// Create by TSMaster

VERSION ""

NS_ :

BS_:

BU_:

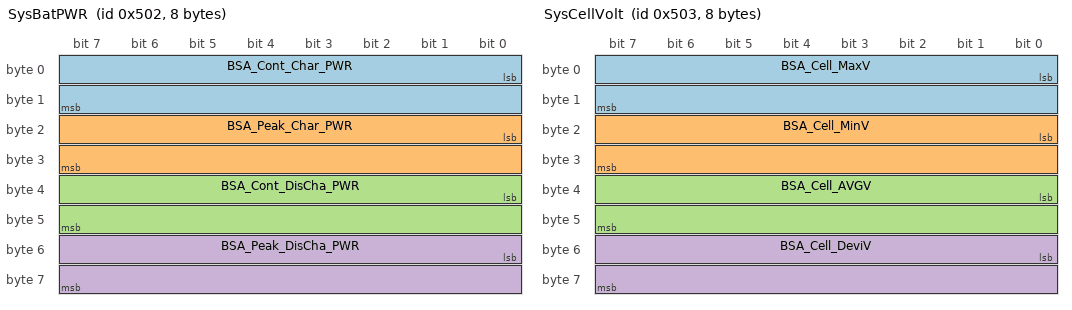
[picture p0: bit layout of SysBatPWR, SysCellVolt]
BO_ 1282 SysBatPWR: 8 Vector__XXX
 SG_ BSA_Cont_Char_PWR : 0|16@1+ (0.1,0) [0.0|200.0] "" Vector__XXX
 SG_ BSA_Peak_Char_PWR : 16|16@1+ (0.1,0) [0.0|300.0] "" Vector__XXX
 SG_ BSA_Cont_DisCha_PWR : 32|16@1+ (0.1,0) [0.0|600.0] "" Vector__XXX
 SG_ BSA_Peak_DisCha_PWR : 48|16@1+ (0.1,0) [0.0|800.0] "" Vector__XXX

BO_ 1283 SysCellVolt: 8 Vector__XXX
 SG_ BSA_Cell_MaxV : 0|16@1+ (0.001,0) [2.8|4.5] "" Vector__XXX
 SG_ BSA_Cell_MinV : 16|16@1+ (0.001,0) [2.8|4.5] "" Vector__XXX
 SG_ BSA_Cell_AVGV : 32|16@1+ (0.001,0) [2.8|4.5] "" Vector__XXX
 SG_ BSA_Cell_DeviV : 48|16@1+ (1.0,0) [0.0|1000.0] "" Vector__XXX

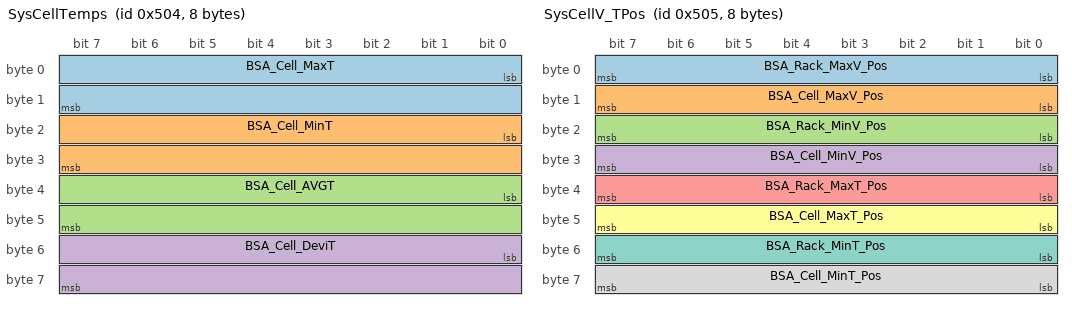
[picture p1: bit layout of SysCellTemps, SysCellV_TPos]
BO_ 1284 SysCellTemps: 8 Vector__XXX
 SG_ BSA_Cell_MaxT : 0|16@1- (0.1,0) [-40.0|100.0] "" Vector__XXX
 SG_ BSA_Cell_MinT : 16|16@1- (0.1,0) [-40.0|100.0] "" Vector__XXX
 SG_ BSA_Cell_AVGT : 32|16@1- (0.1,0) [-40.0|100.0] "" Vector__XXX
 SG_ BSA_Cell_DeviT : 48|16@1+ (0.1,0) [0.0|25.0] "" Vector__XXX

BO_ 1285 SysCellV_TPos: 8 Vector__XXX
 SG_ BSA_Rack_MaxV_Pos : 0|8@1+ (1.0,0) [1.0|10.0] "" Vector__XXX
 SG_ BSA_Cell_MaxV_Pos : 8|8@1+ (1.0,0) [1.0|288.0] "" Vector__XXX
 SG_ BSA_Rack_MinV_Pos : 16|8@1+ (1.0,0) [1.0|10.0] "" Vector__XXX
 SG_ BSA_Cell_MinV_Pos : 24|8@1+ (1.0,0) [1.0|288.0] "" Vector__XXX
 SG_ BSA_Rack_MaxT_Pos : 32|8@1+ (1.0,0) [1.0|10.0] "" Vector__XXX
 SG_ BSA_Cell_MaxT_Pos : 40|8@1+ (1.0,0) [1.0|288.0] "" Vector__XXX
 SG_ BSA_Rack_MinT_Pos : 48|8@1+ (1.0,0) [1.0|10.0] "" Vector__XXX
 SG_ BSA_Cell_MinT_Pos : 56|8@1+ (1.0,0) [1.0|288.0] "" Vector__XXX

BO_ 1286 SysBatProtect: 8 Vector__XXX
 SG_ BSA_Alarm_OC : 0|1@1+ (1.0,0) [0.0|1.0] "" Vector__XXX
 SG_ BSA_Alarm_SOC_OV : 1|1@1+ (1.0,0) [0.0|1.0] "" Vector__XXX
 SG_ BSA_Alarm_SOC_UN : 2|1@1+ (1.0,0) [0.0|1.0] "" Vector__XXX
 SG_ BSA_Alarm_OV : 3|1@1+ (1.0,0) [0.0|1.0] "" Vector__XXX
 SG_ BSA_Alarm_UV : 4|1@1+ (1.0,0) [0.0|1.0] "" Vector__XXX
 SG_ BSA_Alarm_Cell_OV : 5|1@1+ (1.0,0) [0.0|1.0] "" Vector__XXX
 SG_ BSA_Alarm__Cell_UV : 6|1@1+ (1.0,0) [0.0|1.0] "" Vector__XXX
 SG_ BSA_Alarm_Cell_UnBalaV : 7|1@1+ (1.0,0) [0.0|1.0] "" Vector__XXX
 SG_ BSA_Alarm_Dischar_Cell_OT : 8|1@1+ (1.0,0) [0.0|1.0] "" Vector__XXX
 SG_ BSA_Alarm_Char_Cell_OT : 9|1@1+ (1.0,0) [0.0|1.0] "" Vector__XXX
 SG_ BSA_Alarm_Char_Cell_UT : 10|1@1+ (1.0,0) [0.0|1.0] "" Vector__XXX
 SG_ BSA_Alarm_Dischar_Cell_UT : 11|1@1+ (1.0,0) [0.0|1.0] "" Vector__XXX
 SG_ BSA_Alarm_Cell_UnBalaT : 12|1@1+ (1.0,0) [0.0|1.0] "" Vector__XXX
 SG_ BSA_Alarm_Const_OP : 13|1@1+ (1.0,0) [0.0|1.0] "" Vector__XXX
 SG_ BSA_Alarm_Peak_OP : 14|1@1+ (1.0,0) [0.0|1.0] "" Vector__XXX
 SG_ BSA_Fault_OC : 16|1@1+ (1.0,0) [0.0|1.0] "" Vector__XXX
 SG_ BSA_Fault_SOC_OV : 17|1@1+ (1.0,0) [0.0|1.0] "" Vector__XXX
 SG_ BSA_Fault_SOC_UN : 18|1@1+ (1.0,0) [0.0|1.0] "" Vector__XXX
 SG_ BSA_Fault_OV : 19|1@1+ (1.0,0) [0.0|1.0] "" Vector__XXX
 SG_ BSA_Fault_UV : 20|1@1+ (1.0,0) [0.0|1.0] "" Vector__XXX
 SG_ BSA_Fault_Cell_OV : 21|1@1+ (1.0,0) [0.0|1.0] "" Vector__XXX
 SG_ BSA_Fault__Cell_UV : 22|1@1+ (1.0,0) [0.0|1.0] "" Vector__XXX
 SG_ BSA_Fault_Cell_UnBalaV : 23|1@1+ (1.0,0) [0.0|1.0] "" Vector__XXX
 SG_ BSA_Fault_Dischar_Cell_OT : 24|1@1+ (1.0,0) [0.0|1.0] "" Vector__XXX
 SG_ BSA_Fault_Char_Cell_OT : 25|1@1+ (1.0,0) [0.0|1.0] "" Vector__XXX
 SG_ BSA_Fault_Char_Cell_UT : 26|1@1+ (1.0,0) [0.0|1.0] "" Vector__XXX
 SG_ BSA_Fault_Dischar_Cell_UT : 27|1@1+ (1.0,0) [0.0|1.0] "" Vector__XXX
 SG_ BSA_Fault_Cell_UnBalaT : 28|1@1+ (1.0,0) [0.0|1.0] "" Vector__XXX
 SG_ BSA_Fault_Const_OP : 29|1@1+ (1.0,0) [0.0|1.0] "" Vector__XXX
 SG_ BSA_Fault_Peak_OP : 30|1@1+ (1.0,0) [0.0|1.0] "" Vector__XXX
 SG_ BSA_Prtct_OC : 32|1@1+ (1.0,0) [0.0|1.0] "" Vector__XXX
 SG_ BSA_Prtct_SOC_OV : 33|1@1+ (1.0,0) [0.0|1.0] "" Vector__XXX
 SG_ BSA_Prtct_SOC_UN : 34|1@1+ (1.0,0) [0.0|1.0] "" Vector__XXX
 SG_ BSA_Prtct_OV : 35|1@1+ (1.0,0) [0.0|1.0] "" Vector__XXX
 SG_ BSA_Prtct_UV : 36|1@1+ (1.0,0) [0.0|1.0] "" Vector__XXX
 SG_ BSA_Prtct_Cell_OV : 37|1@1+ (1.0,0) [0.0|1.0] "" Vector__XXX
 SG_ BSA_Prtct__Cell_UV : 38|1@1+ (1.0,0) [0.0|1.0] "" Vector__XXX
 SG_ BSA_Prtct_Cell_UnBalaV : 39|1@1+ (1.0,0) [0.0|1.0] "" Vector__XXX
 SG_ BSA_Prtct_Dischar_Cell_OT : 40|1@1+ (1.0,0) [0.0|1.0] "" Vector__XXX
 SG_ BSA_Prtct_Char_Cell_OT : 41|1@1+ (1.0,0) [0.0|1.0] "" Vector__XXX
 SG_ BSA_Prtct_Char_Cell_UT : 42|1@1+ (1.0,0) [0.0|1.0] "" Vector__XXX
 SG_ BSA_Prtct_Dischar_Cell_UT : 43|1@1+ (1.0,0) [0.0|1.0] "" Vector__XXX
 SG_ BSA_Prtct_Cell_UnBalaT : 44|1@1+ (1.0,0) [0.0|1.0] "" Vector__XXX
 SG_ BSA_Prtct_Continuously_OP : 45|1@1+ (1.0,0) [0.0|1.0] "" Vector__XXX
 SG_ BSA_Prtct_Peak_OP : 46|1@1+ (1.0,0) [0.0|1.0] "" Vector__XXX
 SG_ BSA_Prtct_IntCOM : 47|1@1+ (1.0,0) [0.0|1.0] "" Vector__XXX
 SG_ BSA_Prtct_ExtOM : 48|1@1+ (1.0,0) [0.0|1.0] "" Vector__XXX
 SG_ BSA_Prtct_RelayErr : 49|1@1+ (1.0,0) [0.0|1.0] "" Vector__XXX
 SG_ BSA_Prtct_WaterLeak : 50|1@1+ (1.0,0) [0.0|1.0] "" Vector__XXX
 SG_ BSA_Prtct_InsulationReg : 51|1@1+ (1.0,0) [0.0|1.0] "" Vector__XXX
 SG_ BSA_Prtct_MDSFuse : 52|1@1+ (1.0,0) [0.0|1.0] "" Vector__XXX
 SG_ BSA_Prtct_Cooling_System : 53|1@1+ (1.0,0) [0.0|1.0] "" Vector__XXX
 SG_ PMS_PAR_RelayErr : 54|1@1+ (1.0,0) [0.0|1.0] "" Vector__XXX
 SG_ PMS_PAR_SEQErr : 55|1@1+ (1.0,0) [0.0|1.0] "" Vector__XXX
 SG_ BPU_PAR_RelayErr : 56|1@1+ (1.0,0) [0.0|1.0] "" Vector__XXX
 SG_ BRA_PAR_RelayErr : 57|1@1+ (1.0,0) [0.0|1.0] "" Vector__XXX

BO_ 1287 SysBatDIO: 8 Vector__XXX
 SG_ BSA_DO_Prly : 0|1@1+ (1.0,0) [0.0|1.0] "" Vector__XXX
 SG_ BSA_DO_Nrly : 1|1@1+ (1.0,0) [0.0|1.0] "" Vector__XXX
 SG_ BSA_DO_ProRly : 2|1@1+ (1.0,0) [0.0|1.0] "" Vector__XXX
 SG_ BSA_DO_Buzzer : 3|1@1+ (1.0,0) [0.0|1.0] "" Vector__XXX
 SG_ BSA_DO_PwrLamp : 4|1@1+ (1.0,0) [0.0|1.0] "" Vector__XXX
 SG_ BSA_DO_Spare06 : 5|1@1+ (1.0,0) [0.0|1.0] "" Vector__XXX
 SG_ BSA_DO_Spare07 : 6|1@1+ (1.0,0) [0.0|1.0] "" Vector__XXX
 SG_ BSA_DO_Spare08 : 7|1@1+ (1.0,0) [0.0|1.0] "" Vector__XXX
 SG_ BSA_DO_Spare09 : 8|1@1+ (1.0,0) [0.0|1.0] "" Vector__XXX
 SG_ BSA_DO_Spare10 : 9|1@1+ (1.0,0) [0.0|1.0] "" Vector__XXX
 SG_ BSA_DO_Spare11 : 10|1@1+ (1.0,0) [0.0|1.0] "" Vector__XXX
 SG_ BSA_DO_Spare12 : 11|1@1+ (1.0,0) [0.0|1.0] "" Vector__XXX
 SG_ BSA_DI_PRlyAUX : 12|1@1+ (1.0,0) [0.0|1.0] "" Vector__XXX
 SG_ BSA_DI_NRlyAUX : 13|1@1+ (1.0,0) [0.0|1.0] "" Vector__XXX
 SG_ BSA_DI_EMGSw : 14|1@1+ (1.0,0) [0.0|1.0] "" Vector__XXX
 SG_ BSA_DI_CoolSysErr : 15|1@1+ (1.0,0) [0.0|1.0] "" Vector__XXX
 SG_ BSA_DI_MDS : 16|1@1+ (1.0,0) [0.0|1.0] "" Vector__XXX
 SG_ BSA_DI_Spare06 : 17|1@1+ (1.0,0) [0.0|1.0] "" Vector__XXX
 SG_ BSA_DI_Spare07 : 18|1@1+ (1.0,0) [0.0|1.0] "" Vector__XXX
 SG_ BSA_DI_Spare08 : 19|1@1+ (1.0,0) [0.0|1.0] "" Vector__XXX
 SG_ BSA_DI_Spare09 : 20|1@1+ (1.0,0) [0.0|1.0] "" Vector__XXX
 SG_ BSA_DI_Spare10 : 21|1@1+ (1.0,0) [0.0|1.0] "" Vector__XXX
 SG_ BSA_DI_Spare11 : 22|1@1+ (1.0,0) [0.0|1.0] "" Vector__XXX
 SG_ BSA_DI_Spare12 : 23|1@1+ (1.0,0) [0.0|1.0] "" Vector__XXX
 SG_ BSA_SOH : 48|16@1+ (0.1,0) [0.0|100.0] "" Vector__XXX

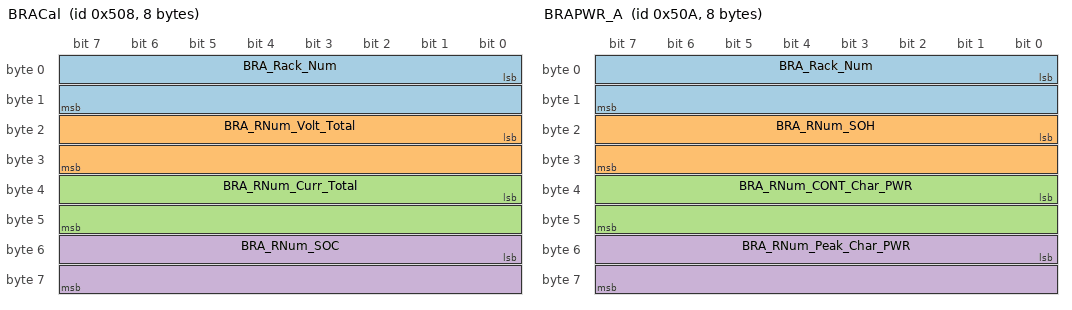
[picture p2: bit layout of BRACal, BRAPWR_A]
BO_ 1288 BRACal: 8 Vector__XXX
 SG_ BRA_Rack_Num : 0|16@1+ (1.0,0) [0.0|10.0] "" Vector__XXX
 SG_ BRA_RNum_Volt_Total : 16|16@1+ (0.1,0) [400.0|800.0] "" Vector__XXX
 SG_ BRA_RNum_Curr_Total : 32|16@1- (0.1,0) [-500.0|500.0] "" Vector__XXX
 SG_ BRA_RNum_SOC : 48|16@1+ (0.1,0) [0.0|100.0] "" Vector__XXX

BO_ 1290 BRAPWR_A: 8 Vector__XXX
 SG_ BRA_Rack_Num : 0|16@1+ (1.0,0) [0.0|10.0] "" Vector__XXX
 SG_ BRA_RNum_SOH : 16|16@1+ (0.1,0) [0.0|100.0] "" Vector__XXX
 SG_ BRA_RNum_CONT_Char_PWR : 32|16@1+ (0.1,0) [0.0|200.0] "" Vector__XXX
 SG_ BRA_RNum_Peak_Char_PWR : 48|16@1+ (0.1,0) [0.0|300.0] "" Vector__XXX

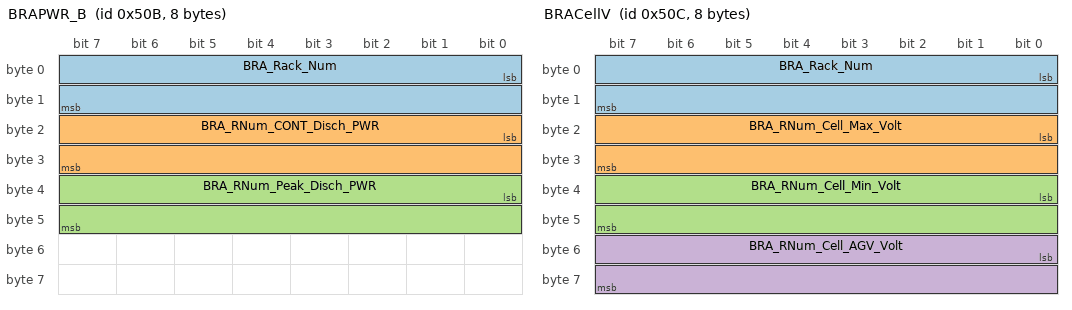
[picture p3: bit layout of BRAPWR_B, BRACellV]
BO_ 1291 BRAPWR_B: 8 Vector__XXX
 SG_ BRA_Rack_Num : 0|16@1+ (1.0,0) [0.0|10.0] "" Vector__XXX
 SG_ BRA_RNum_CONT_Disch_PWR : 16|16@1+ (0.1,0) [0.0|600.0] "" Vector__XXX
 SG_ BRA_RNum_Peak_Disch_PWR : 32|16@1+ (0.1,0) [0.0|800.0] "" Vector__XXX

BO_ 1292 BRACellV: 8 Vector__XXX
 SG_ BRA_Rack_Num : 0|16@1+ (1.0,0) [0.0|10.0] "" Vector__XXX
 SG_ BRA_RNum_Cell_Max_Volt : 16|16@1+ (0.001,0) [2.8|4.5] "" Vector__XXX
 SG_ BRA_RNum_Cell_Min_Volt : 32|16@1+ (0.001,0) [2.8|4.5] "" Vector__XXX
 SG_ BRA_RNum_Cell_AGV_Volt : 48|16@1+ (0.001,0) [2.8|4.5] "" Vector__XXX

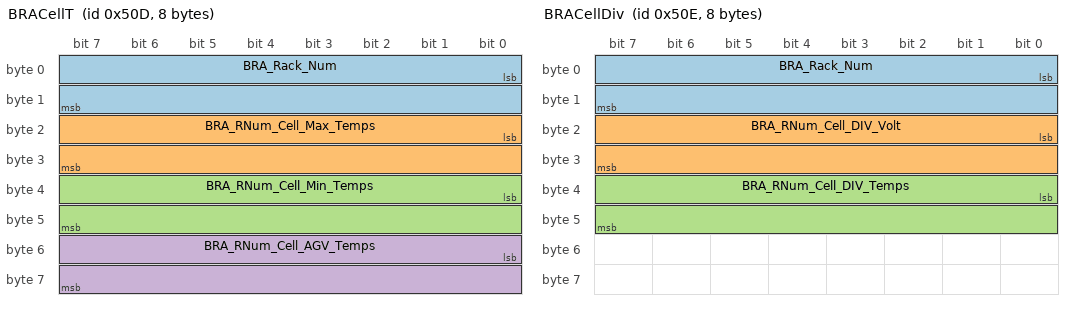
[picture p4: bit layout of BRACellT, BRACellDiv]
BO_ 1293 BRACellT: 8 Vector__XXX
 SG_ BRA_Rack_Num : 0|16@1+ (1.0,0) [0.0|10.0] "" Vector__XXX
 SG_ BRA_RNum_Cell_Max_Temps : 16|16@1- (0.1,0) [-40.0|100.0] "" Vector__XXX
 SG_ BRA_RNum_Cell_Min_Temps : 32|16@1- (0.1,0) [-40.0|100.0] "" Vector__XXX
 SG_ BRA_RNum_Cell_AGV_Temps : 48|16@1- (0.1,0) [-40.0|100.0] "" Vector__XXX

BO_ 1294 BRACellDiv: 8 Vector__XXX
 SG_ BRA_Rack_Num : 0|16@1+ (1.0,0) [0.0|10.0] "" Vector__XXX
 SG_ BRA_RNum_Cell_DIV_Volt : 16|16@1+ (1.0,0) [0.0|1000.0] "" Vector__XXX
 SG_ BRA_RNum_Cell_DIV_Temps : 32|16@1+ (0.1,0) [0.0|25.0] "" Vector__XXX

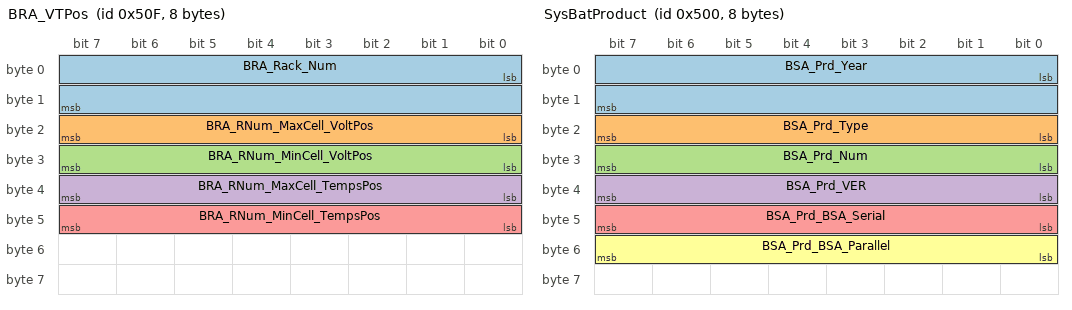
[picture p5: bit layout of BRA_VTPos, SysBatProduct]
BO_ 1295 BRA_VTPos: 8 Vector__XXX
 SG_ BRA_Rack_Num : 0|16@1+ (1.0,0) [0.0|10.0] "" Vector__XXX
 SG_ BRA_RNum_MaxCell_VoltPos : 16|8@1+ (1.0,0) [0.0|288.0] "" Vector__XXX
 SG_ BRA_RNum_MinCell_VoltPos : 24|8@1+ (1.0,0) [0.0|288.0] "" Vector__XXX
 SG_ BRA_RNum_MaxCell_TempsPos : 32|8@1+ (1.0,0) [0.0|288.0] "" Vector__XXX
 SG_ BRA_RNum_MinCell_TempsPos : 40|8@1+ (1.0,0) [0.0|288.0] "" Vector__XXX

BO_ 1296 BAR_Alarm: 8 Vector__XXX
 SG_ BRA_Rack_Num : 0|16@1+ (1.0,0) [0.0|10.0] "" Vector__XXX
 SG_ BRA_RNum_Alarm_OC : 16|1@1+ (1.0,0) [0.0|1.0] "" Vector__XXX
 SG_ BRA_RNum_Alarm_SOC_OV : 17|1@1+ (1.0,0) [0.0|1.0] "" Vector__XXX
 SG_ BRA_RNum_Alarm_SOC_UN : 18|1@1+ (1.0,0) [0.0|1.0] "" Vector__XXX
 SG_ BRA_RNum_Alarm_OV : 19|1@1+ (1.0,0) [0.0|1.0] "" Vector__XXX
 SG_ BRA_RNum_Alarm_UV : 20|1@1+ (1.0,0) [0.0|1.0] "" Vector__XXX
 SG_ BRA_RNum_Alarm_Cell_OV : 21|1@1+ (1.0,0) [0.0|1.0] "" Vector__XXX
 SG_ BRA_RNum_Alarm__Cell_UV : 22|1@1+ (1.0,0) [0.0|1.0] "" Vector__XXX
 SG_ BRA_RNum_Alarm_Cell_UnBalaV : 23|1@1+ (1.0,0) [0.0|1.0] "" Vector__XXX
 SG_ BRA_RNum_Alarm_Disch_Cell_OT : 24|1@1+ (1.0,0) [0.0|1.0] "" Vector__XXX
 SG_ BRA_RNum_Alarm_Char_Cell_OT : 25|1@1+ (1.0,0) [0.0|1.0] "" Vector__XXX
 SG_ BRA_RNum_Alarm_Char_Cell_UT : 26|1@1+ (1.0,0) [0.0|1.0] "" Vector__XXX
 SG_ BRA_RNum_Alarm_Disch_Cell_UT : 27|1@1+ (1.0,0) [0.0|1.0] "" Vector__XXX
 SG_ BRA_RNum_Alarm_Cell_UnBalaT : 28|1@1+ (1.0,0) [0.0|1.0] "" Vector__XXX
 SG_ BRA_RNum_Alarm_Conts_OP : 29|1@1+ (1.0,0) [0.0|1.0] "" Vector__XXX
 SG_ BRA_RNum_Alarm_Peak_OP : 30|1@1+ (1.0,0) [0.0|1.0] "" Vector__XXX
 SG_ BRA_RNum_Fault_OC : 32|1@1+ (1.0,0) [0.0|1.0] "" Vector__XXX
 SG_ BRA_RNum_Fault_SOC_OV : 33|1@1+ (1.0,0) [0.0|1.0] "" Vector__XXX
 SG_ BRA_RNum_Fault_SOC_UN : 34|1@1+ (1.0,0) [0.0|1.0] "" Vector__XXX
 SG_ BRA_RNum_Fault_OV : 35|1@1+ (1.0,0) [0.0|1.0] "" Vector__XXX
 SG_ BRA_RNum_Fault_UV : 36|1@1+ (1.0,0) [0.0|1.0] "" Vector__XXX
 SG_ BRA_RNum_Fault_Cell_OV : 37|1@1+ (1.0,0) [0.0|1.0] "" Vector__XXX
 SG_ BRA_RNum_Fault__Cell_UV : 38|1@1+ (1.0,0) [0.0|1.0] "" Vector__XXX
 SG_ BRA_RNum_Fault_Cell_UnBalaV : 39|1@1+ (1.0,0) [0.0|1.0] "" Vector__XXX
 SG_ BRA_RNum_Fault_Disch_Cell_OT : 40|1@1+ (1.0,0) [0.0|1.0] "" Vector__XXX
 SG_ BRA_RNum_Fault_Char_Cell_OT : 41|1@1+ (1.0,0) [0.0|1.0] "" Vector__XXX
 SG_ BRA_RNum_Fault_Char_Cell_UT : 42|1@1+ (1.0,0) [0.0|1.0] "" Vector__XXX
 SG_ BRA_RNum_Fault_Disch_Cell_UT : 43|1@1+ (1.0,0) [0.0|1.0] "" Vector__XXX
 SG_ BRA_RNum_Fault_Cell_UnBalaT : 44|1@1+ (1.0,0) [0.0|1.0] "" Vector__XXX
 SG_ BRA_RNum_Fault_Conts_OP : 45|1@1+ (1.0,0) [0.0|1.0] "" Vector__XXX
 SG_ BRA_RNum_Fault_Peak_OP : 46|1@1+ (1.0,0) [0.0|1.0] "" Vector__XXX

BO_ 1297 BAR_Protect: 8 Vector__XXX
 SG_ BRA_Rack_Num : 0|16@1+ (1.0,0) [0.0|10.0] "" Vector__XXX
 SG_ BRA_RNum_Prtct_OC : 16|1@1+ (1.0,0) [0.0|1.0] "" Vector__XXX
 SG_ BRA_RNum_Prtct_SOC_OV : 17|1@1+ (1.0,0) [0.0|1.0] "" Vector__XXX
 SG_ BRA_RNum_Prtct_SOC_UN : 18|1@1+ (1.0,0) [0.0|1.0] "" Vector__XXX
 SG_ BRA_RNum_Prtct_OV : 19|1@1+ (1.0,0) [0.0|1.0] "" Vector__XXX
 SG_ BRA_RNum_Prtct_UV : 20|1@1+ (1.0,0) [0.0|1.0] "" Vector__XXX
 SG_ BRA_RNum_Prtct_Cell_OV : 21|1@1+ (1.0,0) [0.0|1.0] "" Vector__XXX
 SG_ BRA_RNum_Prtct__Cell_UV : 22|1@1+ (1.0,0) [0.0|1.0] "" Vector__XXX
 SG_ BRA_RNum_Prtct_Cell_UnBalaV : 23|1@1+ (1.0,0) [0.0|1.0] "" Vector__XXX
 SG_ BRA_RNum_Prtct_Disch_Cell_OT : 24|1@1+ (1.0,0) [0.0|1.0] "" Vector__XXX
 SG_ BRA_RNum_Prtct_Char_Cell_OT : 25|1@1+ (1.0,0) [0.0|1.0] "" Vector__XXX
 SG_ BRA_RNum_Prtct_Char_Cell_UT : 26|1@1+ (1.0,0) [0.0|1.0] "" Vector__XXX
 SG_ BRA_RNum_Prtct_Disch_Cell_UT : 27|1@1+ (1.0,0) [0.0|1.0] "" Vector__XXX
 SG_ BRA_RNum_Prtct_Cell_UnBalaT : 28|1@1+ (1.0,0) [0.0|1.0] "" Vector__XXX
 SG_ BRA_RNum_Prtct_Conts_OP : 29|1@1+ (1.0,0) [0.0|1.0] "" Vector__XXX
 SG_ BRA_RNum_Prtct_Peak_OP : 30|1@1+ (1.0,0) [0.0|1.0] "" Vector__XXX
 SG_ BRA_RNum_Prtct_IntCOM : 31|1@1+ (1.0,0) [0.0|1.0] "" Vector__XXX
 SG_ BRA_RNum_Prtct_ExtCOM : 32|1@1+ (1.0,0) [0.0|1.0] "" Vector__XXX
 SG_ BRA_RNum_Prtct_RelayErr : 33|1@1+ (1.0,0) [0.0|1.0] "" Vector__XXX
 SG_ BRA_RNum_Prtct_WaterLeak : 34|1@1+ (1.0,0) [0.0|1.0] "" Vector__XXX
 SG_ BRA_RNum_Prtct_ISOReg : 35|1@1+ (1.0,0) [0.0|1.0] "" Vector__XXX
 SG_ BRA_RNum_Prtct_MDSFuse : 36|1@1+ (1.0,0) [0.0|1.0] "" Vector__XXX
 SG_ BRA_RNum_Prtct_CoolSys : 37|1@1+ (1.0,0) [0.0|1.0] "" Vector__XXX

BO_ 1298 BAR_DIO: 8 Vector__XXX
 SG_ BRA_Rack_Num : 0|16@1+ (1.0,0) [0.0|10.0] "" Vector__XXX
 SG_ BRA_RNum_DO_PRly : 16|1@1+ (1.0,0) [0.0|1.0] "" Vector__XXX
 SG_ BRA_RNum_DO_NRly : 17|1@1+ (1.0,0) [0.0|1.0] "" Vector__XXX
 SG_ BRA_RNum_DO_ProRly : 18|1@1+ (1.0,0) [0.0|1.0] "" Vector__XXX
 SG_ BRA_RNum_DO_PWRLamp : 19|1@1+ (1.0,0) [0.0|1.0] "" Vector__XXX
 SG_ BRA_RNum_DO_Buzzer : 20|1@1+ (1.0,0) [0.0|1.0] "" Vector__XXX
 SG_ BRA_RNum_DI_PRlyAUX : 32|1@1+ (1.0,0) [0.0|1.0] "" Vector__XXX
 SG_ BRA_RNum_DI_NRlyAUX : 33|1@1+ (1.0,0) [0.0|1.0] "" Vector__XXX
 SG_ BRA_RNum_DI_EMGSW : 34|1@1+ (1.0,0) [0.0|1.0] "" Vector__XXX
 SG_ BRA_RNum_DI_MDS : 35|1@1+ (1.0,0) [0.0|1.0] "" Vector__XXX
 SG_ BRA_RNum_MD1_Wateak : 48|1@1+ (1.0,0) [0.0|1.0] "" Vector__XXX
 SG_ BRA_RNum_MD2_Wateak : 49|1@1+ (1.0,0) [0.0|1.0] "" Vector__XXX
 SG_ BRA_RNum_MD3_Wateak : 50|1@1+ (1.0,0) [0.0|1.0] "" Vector__XXX
 SG_ BRA_RNum_MD4_Wateak : 51|1@1+ (1.0,0) [0.0|1.0] "" Vector__XXX
 SG_ BRA_RNum_MD5_Wateak : 52|1@1+ (1.0,0) [0.0|1.0] "" Vector__XXX
 SG_ BRA_RNum_MD6_Wateak : 53|1@1+ (1.0,0) [0.0|1.0] "" Vector__XXX
 SG_ BRA_RNum_MD7_Wateak : 54|1@1+ (1.0,0) [0.0|1.0] "" Vector__XXX

BO_ 1280 SysBatProduct: 8 Vector__XXX
 SG_ BSA_Prd_Year : 0|16@1+ (1.0,0) [2000.0|2050.0] "" Vector__XXX
 SG_ BSA_Prd_Type : 16|8@1+ (1.0,0) [0.0|20.0] "" Vector__XXX
 SG_ BSA_Prd_Num : 24|8@1+ (1.0,0) [0.0|255.0] "" Vector__XXX
 SG_ BSA_Prd_VER : 32|8@1+ (0.1,0) [0.0|25.0] "" Vector__XXX
 SG_ BSA_Prd_BSA_Serial : 40|8@1+ (1.0,0) [0.0|288.0] "" Vector__XXX
 SG_ BSA_Prd_BSA_Parallel : 48|8@1+ (1.0,0) [0.0|10.0] "" Vector__XXX

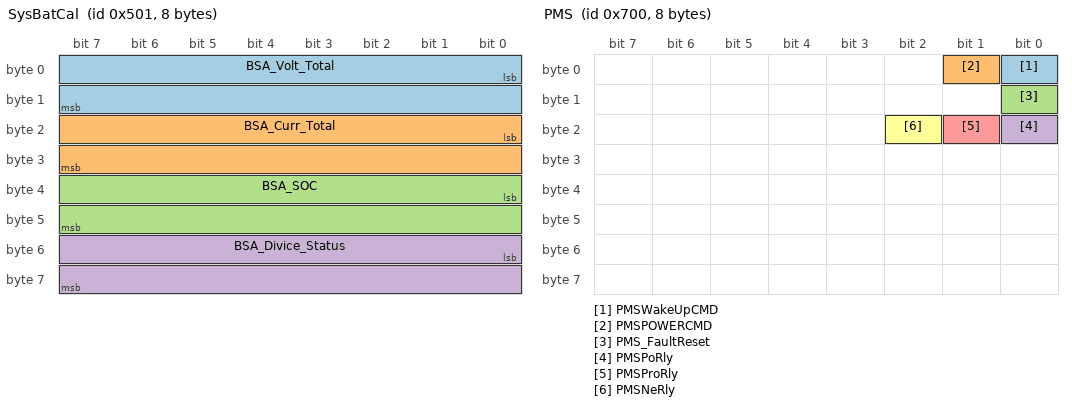
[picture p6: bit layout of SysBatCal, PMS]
BO_ 1281 SysBatCal: 8 Vector__XXX
 SG_ BSA_Volt_Total : 0|16@1+ (0.1,0) [400.0|800.0] "" Vector__XXX
 SG_ BSA_Curr_Total : 16|16@1- (0.1,0) [-500.0|500.0] "" Vector__XXX
 SG_ BSA_SOC : 32|16@1+ (0.1,0) [0.0|100.0] "" Vector__XXX
 SG_ BSA_Divice_Status : 48|16@1+ (1.0,0) [0.0|10.0] "" Vector__XXX

BO_ 1792 PMS: 8 Vector__XXX
 SG_ PMSWakeUpCMD : 0|1@1+ (1.0,0) [0.0|1.0] "" Vector__XXX
 SG_ PMSPOWERCMD : 1|1@1+ (1.0,0) [0.0|1.0] "" Vector__XXX
 SG_ PMS_FaultReset : 8|1@1+ (1.0,0) [0.0|1.0] "" Vector__XXX
 SG_ PMSPoRly : 16|1@1+ (1.0,0) [0.0|1.0] "" Vector__XXX
 SG_ PMSProRly : 17|1@1+ (1.0,0) [0.0|1.0] "" Vector__XXX
 SG_ PMSNeRly : 18|1@1+ (1.0,0) [0.0|1.0] "" Vector__XXX
